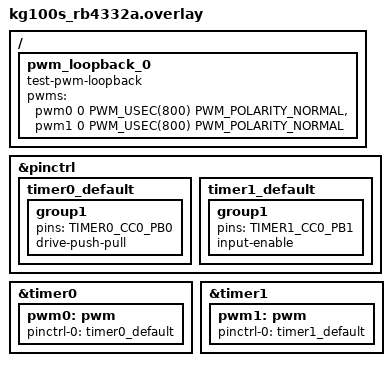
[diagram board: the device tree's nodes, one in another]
/*
 * Copyright (c) 2026 Martin Moya <martin.moya@focus.uy>
 *
 * SPDX-License-Identifier: Apache-2.0
 */

#include <zephyr/dt-bindings/pwm/pwm.h>
#include <zephyr/dt-bindings/pinctrl/silabs/xg21-pinctrl.h>

/* Connections:
 * PB0 - PB1: TIMER0 (PB0, output) to TIMER1 (PB1, capture input)
 * correspondent to EXP_HEADER16 and EXP_HEADER15
 *
 * TIMER0 is 32-bit and used as output; TIMER1 is 16-bit and used as
 * capture input. The test period is reduced via kg100s_rb4332a.conf to
 * fit in TIMER1's 16-bit counter at the 76.8 MHz EM01GRPACLK.
 */

/ {
	pwm_loopback_0 {
		compatible = "test-pwm-loopback";
		pwms = <&pwm0 0 PWM_USEC(800) PWM_POLARITY_NORMAL>,
		       <&pwm1 0 PWM_USEC(800) PWM_POLARITY_NORMAL>;
	};
};

&pinctrl {
	timer0_default: timer0_default {
		group1 {
			pins = <TIMER0_CC0_PB0>;
			drive-push-pull;
		};
	};

	timer1_default: timer1_default {
		group1 {
			pins = <TIMER1_CC0_PB1>;
			input-enable;
		};
	};
};

&timer0 {
	status = "okay";

	pwm0: pwm {
		pinctrl-0 = <&timer0_default>;
		pinctrl-names = "default";
		status = "okay";
	};
};

&timer1 {
	status = "okay";

	pwm1: pwm {
		pinctrl-0 = <&timer1_default>;
		pinctrl-names = "default";
		status = "okay";
	};
};
